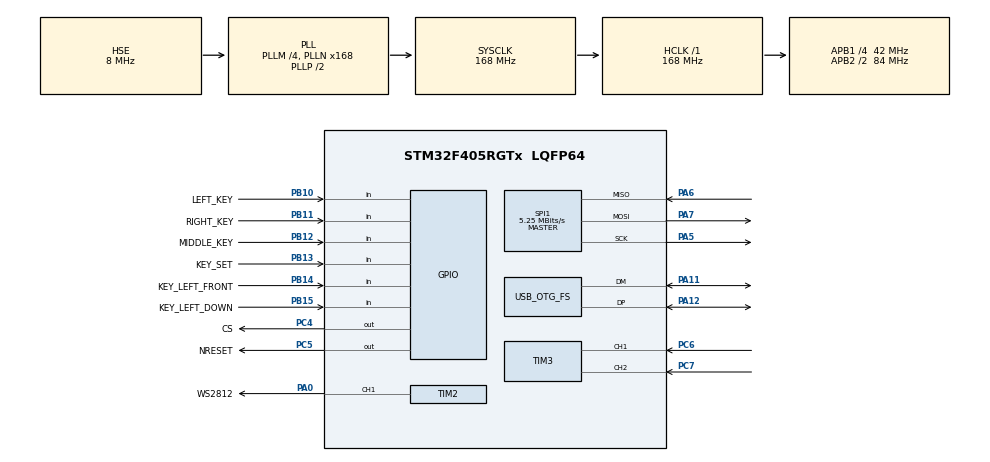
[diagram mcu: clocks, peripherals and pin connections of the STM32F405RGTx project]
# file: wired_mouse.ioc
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Dma.Request0=TIM2_CH1
Dma.TIM2_CH1.0.Direction=DMA_MEMORY_TO_PERIPH
Dma.TIM2_CH1.0.FIFOMode=DMA_FIFOMODE_DISABLE
Dma.TIM2_CH1.0.Instance=DMA1_Stream5
Dma.TIM2_CH1.0.MemDataAlignment=DMA_MDATAALIGN_WORD
Dma.TIM2_CH1.0.MemInc=DMA_MINC_ENABLE
Dma.TIM2_CH1.0.Mode=DMA_NORMAL
Dma.TIM2_CH1.0.PeriphDataAlignment=DMA_PDATAALIGN_WORD
Dma.TIM2_CH1.0.PeriphInc=DMA_PINC_DISABLE
Dma.TIM2_CH1.0.Priority=DMA_PRIORITY_HIGH
Mcu.Family=STM32F4
Mcu.Name=STM32F405RGTx
Mcu.Package=LQFP64
NVIC.DMA1_Stream5_IRQn=true\:5\:0\:true\:false\:true\:false\:false\:true\:true
NVIC.OTG_FS_IRQn=true\:0\:0\:true\:false\:true\:false\:true\:true\:true
NVIC.PriorityGroup=NVIC_PRIORITYGROUP_4
NVIC.TIM4_IRQn=true\:15\:0\:false\:false\:true\:false\:false\:true\:true
NVIC.TIM6_DAC_IRQn=true\:1\:0\:true\:false\:true\:false\:true\:true\:true
NVIC.TimeBase=TIM4_IRQn
NVIC.TimeBaseIP=TIM4
PA0-WKUP.GPIO_Label=WS2812
PA0-WKUP.GPIO_PuPd=GPIO_NOPULL
PA0-WKUP.GPIO_Speed=GPIO_SPEED_FREQ_HIGH
PA0-WKUP.Signal=S_TIM2_CH1_ETR
PA11.Mode=Device_Only
PA11.Signal=USB_OTG_FS_DM
PA12.GPIO_PuPd=GPIO_PULLUP
PA12.Mode=Device_Only
PA12.Signal=USB_OTG_FS_DP
PA5.Mode=Full_Duplex_Master
PA5.Signal=SPI1_SCK
PA6.GPIO_PuPd=GPIO_PULLUP
PA6.Mode=Full_Duplex_Master
PA6.Signal=SPI1_MISO
PA7.Mode=Full_Duplex_Master
PA7.Signal=SPI1_MOSI
PB10.GPIO_Label=LEFT_KEY
PB10.GPIO_PuPd=GPIO_PULLUP
PB10.Signal=GPIO_Input
PB11.GPIO_Label=RIGHT_KEY
PB11.GPIO_PuPd=GPIO_PULLUP
PB11.Signal=GPIO_Input
PB12.GPIO_Label=MIDDLE_KEY
PB12.GPIO_PuPd=GPIO_PULLUP
PB12.Signal=GPIO_Input
PB13.GPIO_Label=KEY_SET
PB13.GPIO_PuPd=GPIO_PULLUP
PB13.Signal=GPIO_Input
PB14.GPIO_Label=KEY_LEFT_FRONT
PB14.GPIO_PuPd=GPIO_PULLUP
PB14.Signal=GPIO_Input
PB15.GPIO_Label=KEY_LEFT_DOWN
PB15.GPIO_PuPd=GPIO_PULLUP
PB15.Signal=GPIO_Input
PC4.GPIO_Label=CS
PC4.GPIO_PuPd=GPIO_PULLUP
PC4.GPIO_Speed=GPIO_SPEED_FREQ_MEDIUM
PC4.PinState=GPIO_PIN_SET
PC4.Signal=GPIO_Output
PC5.GPIO_Label=NRESET
PC5.GPIO_PuPd=GPIO_PULLUP
PC5.GPIO_Speed=GPIO_SPEED_FREQ_MEDIUM
PC5.Signal=GPIO_Output
PC6.GPIO_Speed=GPIO_SPEED_FREQ_HIGH
PC6.Signal=S_TIM3_CH1
PC7.GPIO_Speed=GPIO_SPEED_FREQ_HIGH
PC7.Signal=S_TIM3_CH2
PH0-OSC_IN.Mode=HSE-External-Oscillator
PH0-OSC_IN.Signal=RCC_OSC_IN
PH1-OSC_OUT.Mode=HSE-External-Oscillator
PH1-OSC_OUT.Signal=RCC_OSC_OUT
ProjectManager.HeapSize=0x200
ProjectManager.StackSize=0x400
ProjectManager.TargetToolchain=MDK-ARM V5.32
RCC.48MHZClocksFreq_Value=48000000
RCC.AHBFreq_Value=168000000
RCC.APB1CLKDivider=RCC_HCLK_DIV4
RCC.APB1Freq_Value=42000000
RCC.APB1TimFreq_Value=84000000
RCC.APB2CLKDivider=RCC_HCLK_DIV2
RCC.APB2Freq_Value=84000000
RCC.APB2TimFreq_Value=168000000
RCC.CortexFreq_Value=168000000
RCC.HCLKFreq_Value=168000000
RCC.HSE_VALUE=8000000
RCC.HSI_VALUE=16000000
RCC.LSE_VALUE=32768
RCC.PLLM=4
RCC.PLLN=168
RCC.PLLQ=7
RCC.SYSCLKFreq_VALUE=168000000
RCC.SYSCLKSource=RCC_SYSCLKSOURCE_PLLCLK
RCC.VCOOutputFreq_Value=336000000
SH.S_TIM2_CH1_ETR.0=TIM2_CH1,PWM Generation1 CH1
SH.S_TIM3_CH1.0=TIM3_CH1,Encoder_Interface
SH.S_TIM3_CH2.0=TIM3_CH2,Encoder_Interface
SPI1.BaudRatePrescaler=SPI_BAUDRATEPRESCALER_16
SPI1.CLKPhase=SPI_PHASE_2EDGE
SPI1.CLKPolarity=SPI_POLARITY_HIGH
SPI1.CalculateBaudRate=5.25 MBits/s
SPI1.Direction=SPI_DIRECTION_2LINES
SPI1.Mode=SPI_MODE_MASTER
SPI1.VirtualType=VM_MASTER
STMicroelectronics.X-CUBE-AZRTOS-F4.1.1.0.TX_APP_MEM_POOL_SIZE=8192
STMicroelectronics.X-CUBE-AZRTOS-F4.1.1.0.TX_TIMER_TICKS_PER_SECOND=200
STMicroelectronics.X-CUBE-AZRTOS-F4.1.1.0.ThreadXCcRTOSJjThreadXJjCore=true
STMicroelectronics.X-CUBE-AZRTOS-F4.1.1.0.USBD_HID_EPIN_FS_BINTERVAL=1
STMicroelectronics.X-CUBE-AZRTOS-F4.1.1.0.USBD_HID_EPIN_FS_MPS=6
STMicroelectronics.X-CUBE-AZRTOS-F4.1.1.0.USBD_HID_EPIN_HS_BINTERVAL=1
STMicroelectronics.X-CUBE-AZRTOS-F4.1.1.0.USBD_HID_EPIN_HS_MPS=6
STMicroelectronics.X-CUBE-AZRTOS-F4.1.1.0.USBXCcUSBJjUSBXJjCoreSystem=true
STMicroelectronics.X-CUBE-AZRTOS-F4.1.1.0.USBXCcUSBJjUSBXJjUXOoDeviceOoClassOoHID=true
STMicroelectronics.X-CUBE-AZRTOS-F4.1.1.0.USBXCcUSBJjUSBXJjUXOoDeviceOoControllers=true
STMicroelectronics.X-CUBE-AZRTOS-F4.1.1.0.USBXCcUSBJjUSBXJjUXOoDeviceOoCoreStack=true
STMicroelectronics.X-CUBE-AZRTOS-F4.1.1.0.UX_DEVICE_APP_MEM_POOL_SIZE=16384
STMicroelectronics.X-CUBE-AZRTOS-F4.1.1.0.UX_THREAD_PRIORITY_CLASS=10
STMicroelectronics.X-CUBE-AZRTOS-F4.1.1.0_IsAnAzureRtosMw=true
TIM2.AutoReloadPreload=TIM_AUTORELOAD_PRELOAD_ENABLE
TIM2.Channel-PWM\ Generation1\ CH1=TIM_CHANNEL_1
TIM2.Period=104
TIM3.EncoderMode=TIM_ENCODERMODE_TI12
TIM3.IC1Filter=3
TIM3.IC2Filter=3
TIM6.AutoReloadPreload=TIM_AUTORELOAD_PRELOAD_ENABLE
TIM6.Period=1000-1
TIM6.Prescaler=84-1
USB_OTG_FS.VirtualMode=Device_Only
VP_STMicroelectronics.X-CUBE-AZRTOS-F4_VS_RTOSJjThreadX_6.1.10_1.1.0.Mode=RTOSJjThreadX
VP_STMicroelectronics.X-CUBE-AZRTOS-F4_VS_USBJjUSBX_6.1.10_1.1.0.Mode=USBJjUSBX
VP_SYS_VS_tim4.Mode=TIM4
VP_TIM2_VS_ClockSourceINT.Mode=Internal
VP_TIM6_VS_ClockSourceINT.Mode=Enable_Timer
board=custom

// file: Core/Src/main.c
/* USER CODE BEGIN Header */
/**
  ******************************************************************************
  * @file           : main.c
  * @brief          : Main program body
  ******************************************************************************
  * @attention
  *
  * Copyright (c) 2026 STMicroelectronics.
  * All rights reserved.
  *
  * This software is licensed under terms that can be found in the LICENSE file
  * in the root directory of this software component.
  * If no LICENSE file comes with this software, it is provided AS-IS.
  *
  ******************************************************************************
  */
/* USER CODE END Header */
#include "app_threadx.h"
#include "main.h"
#include "dma.h"
#include "spi.h"
#include "tim.h"
#include "usb_otg.h"
#include "gpio.h"

/* USER CODE BEGIN Includes */
#include "threadx_tasks.h"
/* USER CODE END Includes */

/* USER CODE BEGIN PTD */
#include "stm32f4xx.h"
/* USER CODE END PTD */

void SystemClock_Config(void);

int main(void)
{

  /* MCU Configuration--------------------------------------------------------*/

  /* Reset of all peripherals, Initializes the Flash interface and the Systick. */
  HAL_Init();

  /* Configure the system clock */
  SystemClock_Config();

  /* Initialize all configured peripherals */
  MX_GPIO_Init();
  MX_DMA_Init();
  MX_TIM3_Init();
  MX_TIM2_Init();
  MX_SPI1_Init();
  MX_TIM6_Init();
  MX_USB_OTG_FS_PCD_Init();
  /* USER CODE BEGIN 2 */
  HAL_TIM_Base_Start_IT(&htim6);
  /* USER CODE END 2 */

  MX_ThreadX_Init();

  /* We should never get here as control is now taken by the scheduler */

  /* Infinite loop */
  while (1)
  {

  }
}

void SystemClock_Config(void)
{
  RCC_OscInitTypeDef RCC_OscInitStruct = {0};
  RCC_ClkInitTypeDef RCC_ClkInitStruct = {0};

  /** Configure the main internal regulator output voltage
  */
  __HAL_RCC_PWR_CLK_ENABLE();
  __HAL_PWR_VOLTAGESCALING_CONFIG(PWR_REGULATOR_VOLTAGE_SCALE1);

  /** Initializes the RCC Oscillators according to the specified parameters
  * in the RCC_OscInitTypeDef structure.
  */
  RCC_OscInitStruct.OscillatorType = RCC_OSCILLATORTYPE_HSE;
  RCC_OscInitStruct.HSEState = RCC_HSE_ON;
  RCC_OscInitStruct.PLL.PLLState = RCC_PLL_ON;
  RCC_OscInitStruct.PLL.PLLSource = RCC_PLLSOURCE_HSE;
  RCC_OscInitStruct.PLL.PLLM = 4;
  RCC_OscInitStruct.PLL.PLLN = 168;
  RCC_OscInitStruct.PLL.PLLP = RCC_PLLP_DIV2;
  RCC_OscInitStruct.PLL.PLLQ = 7;
  if (HAL_RCC_OscConfig(&RCC_OscInitStruct) != HAL_OK)
  {
    Error_Handler();
  }

  /** Initializes the CPU, AHB and APB buses clocks
  */
  RCC_ClkInitStruct.ClockType = RCC_CLOCKTYPE_HCLK|RCC_CLOCKTYPE_SYSCLK
                              |RCC_CLOCKTYPE_PCLK1|RCC_CLOCKTYPE_PCLK2;
  RCC_ClkInitStruct.SYSCLKSource = RCC_SYSCLKSOURCE_PLLCLK;
  RCC_ClkInitStruct.AHBCLKDivider = RCC_SYSCLK_DIV1;
  RCC_ClkInitStruct.APB1CLKDivider = RCC_HCLK_DIV4;
  RCC_ClkInitStruct.APB2CLKDivider = RCC_HCLK_DIV2;

  if (HAL_RCC_ClockConfig(&RCC_ClkInitStruct, FLASH_LATENCY_5) != HAL_OK)
  {
    Error_Handler();
  }
}

void HAL_TIM_PeriodElapsedCallback(TIM_HandleTypeDef *htim)
{
  if (htim->Instance == TIM4)
  {
    HAL_IncTick();
  }
  /* USER CODE BEGIN Callback 1 */
  if (htim->Instance == TIM6)
  {
    tx_event_flags_set(&event_group,TIME_TO_SEND_DATA_TO_PC, TX_OR);
  }
  /* USER CODE END Callback 1 */
}

void Error_Handler(void)
{
  __disable_irq();
  while (1)
  {
  }
}
